# FLASH register map
Vendor: Texas Instruments
Peripheral module from a debugger description file (folder UCD3138R032RSM).
Registers are 32-bit, read-write, no defined reset value unless marked. A register's access mark holds for its fields unless they carry their own. Offsets are as the file gives them; lines under a group give offsets from that group; [hi:lo] are bit positions; {n}, {i} and the like mark numbered series; 'fields as' and 'values as' point back to an identical list; <NAME> marks a mode.

## FLASH (part 1 of 2) — This is the MMR space for the flash wrapper. The flash wrapper is targeting multiple microcontroller platforms. The flash wrapper is a module that manages complex flash read, program and erase memory operations. The system is also given direct access to read flash memory contents directly for each instantiated flash bank through FBAP ports.
0x00 DFTEN — DFT Enable Register Allows control of flash wrapper test features. When set, DFT* registers in this aperture open for write access. When cleared, DFT* registers are read-only. This register is blocked for writes after a 1 is written to the CMDEXEC register and prior to STATCMD.DONE being set by the flash wrapper hardware.
  [0] ENABLE — Enable Test Features
    0=DISABLED (Command); 1=ENABLED (Command)
0x00 CMDEXEC — Command Execute Register: Initiates execution of the command specified in the CMDTYPE register. This register is blocked for writes after being written to 1 and prior to STATCMD.DONE being set by the flash wrapper hardware. flash wrapper hardware clears this register after the processing of the command has completed.
  [0] VAL — Command Execute value Initiates execution of the command specified in the CMDTYPE register.
    0=NOEXECUTE (Command will not execute or is not executing in flash wrapper); 1=EXECUTE (Command will execute or is executing in flash wrapper)
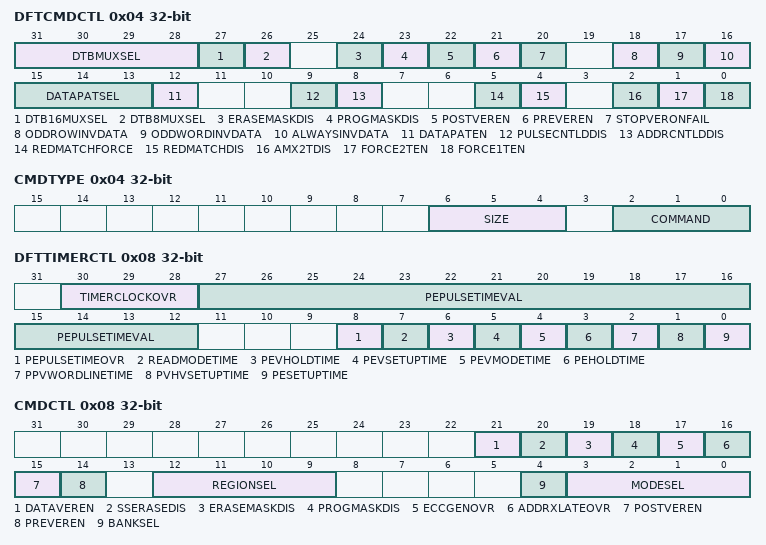
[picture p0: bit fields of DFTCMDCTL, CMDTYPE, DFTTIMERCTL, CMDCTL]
0x04 DFTCMDCTL — DFT Command Control Register This register configures specific capabilities for test. This register is only writable when DFTEN.ENABLE is set. This register is blocked for writes after a 1 is written to the CMDEXEC register and prior to STATCMD.DONE being set by the flash wrapper hardware.
  [31:28] DTBMUXSEL — DTB Mux Select This field will form the select for the primary DTB mux. This mux selects up to 16 sets of 32-bit fields of internal signals to be present to the 32-bit DTB output.
    15=MAXIMUM (Maximum value); 0=MINIMUM (Minimum value)
  [27] DTB16MUXSEL — DTB16 Mux Select This bit is valid when the flash wrapper DTB output bus width is less than 32 bits. Specifically, this bit is valid when the DTB width is 16 bits or less. When this is the case, then DTB16MUXSEL is used to select either the upper or lower 16-bit portion of the native 32-bit DTB bus. 8-bit portion of the 16-bit DTB value.
    1=UPPER16BITS (Select upper 16 bits of 32-bit DTB); 0=LOWER16BITS (Select lower 16 bits of 32-bit DTB)
  [26] DTB8MUXSEL — DTB8 Mux Select This bit is valid when the flash wrapper DTB output bus width is less than 32 bits. Specifically, this bit is valid when the DTB width is 8 bits. When this is the case, then DTB16MUXSEL is used to select either the upper or lower 16-bit portion of the native 32-bit DTB bus. DTB8MUXSEL is then used to select the upper or lower 8-bit portion of the 16-bit DTB value.
    1=UPPER8BITS (Select upper 8 bits of 16-bit DTB); 0=LOWER8BITS (Select lower 8 bits of 16-bit DTB)
  [24] ERASEMASKDIS — Disable use of erase mask for erase Bit masking will not be used during erase verify. If any sectors fail the verify either before (prever) or after (postver) the operation, then all specified flash sectors will receive subsequent erase pulse.
    0=ENABLE; 1=DISABLE
  [23] PROGMASKDIS — Disable use of program mask for programming. Bit masking will not be used during program verify. If any bits fail the verify either before (prever) or after (postver) the operation, then all specified flash entries will receive subsequent program pulse.
    0=ENABLE; 1=DISABLE
  [22] POSTVEREN — Enable verify after program or erase
    0=DISABLE; 1=ENABLE
  [21] PREVEREN — Enable verify before program or erase. For program, bits already programmed to the requested value will be masked. For erase, sectors already erased will be masked.
    0=DISABLE; 1=ENABLE
  [20] STOPVERONFAIL — Stop verify on fail. If this bit is set, verify will halt when the first verify fail is detected. If command is program or erase, another program or erase pulse will be executed. If command is ReadVerify, comand will terminate.
    0=DISABLE; 1=ENABLE
  [18] ODDROWINVDATA — Invert data at odd row addresses for program or verify. The LSB of the row address is bit [4] of the bank address. This bit only applies when pattern data is used; i.e. the DATAPATEN bit is set. It will have no effect if CMDDATA is used.
    0=TRUE (Use true data); 1=INVERT (Use inverted data)
  [17] ODDWORDINVDATA — Invert data at odd bank addresses for program or verify. This bit only applies when pattern data is used; i.e. the DATAPATEN bit is set. It will have no effect if CMDDATA is used.
    0=TRUE (Use true data); 1=INVERT (Use inverted data)
  [16] ALWAYSINVDATA — Invert data always for program or verify. This bit only applies when pattern data is used; i.e. the DATAPATEN bit is set. It will have no effect if CMDDATA is used.
    0=TRUE (Use true data); 1=INVERT (Use inverted data)
  [15:13] DATAPATSEL — Select data pattern. Valid when DATAPATEN bit is set to 1. Overrides CMDDATA registers for program or verify.
    0=ALL0 (Set to all 0); 1=ALL1 (Set to all 1); 2=LOGCHKBRD (Set to logical checkerboard (0x01010101...))
  [12] DATAPATEN — Enable data pattern. Data pattern select in DATAPATSEL field will override data from CMDDATA registers for use as program or verify data.
    0=DISABLE; 1=ENABLE
  [9] PULSECNTLDDIS — Override pulse counter enable. When set, the state machine pulse counter will not be loaded when a command is initiated.
    0=ENABLE; 1=DISABLE
  [8] ADDRCNTLDDIS — Override address counter enable. When set, the state machine address counter will not be loaded when a command is initiated.
    0=ENABLE; 1=DISABLE
  [5] REDMATCHFORCE — Force redundancy match. If set to 1, repair configuration encoded in the flash bank trim will be forced for every access.
    0=DISABLE; 1=ENABLE
  [4] REDMATCHDIS — Disable redundancy matching. Any repair configuration encoded into the bank trim bits is disabled.
    0=ENABLE; 1=DISABLE
  [2] AMX2TDIS — 2T address mux disable control. When set to 1 2T address shifting is disabled. This bit can only be enabled for reads. Indeterminate behavior will result if this bit is set during program/erase.
    0=ENABLE; 1=DISABLE
  [1] FORCE2TEN — Force 2T Enable - Force 2T access to regions that are designated as 1T. Regions designated as 2T will still be accessed as 2T.
    0=DISABLE; 1=ENABLE
  [0] FORCE1TEN — Force 1T Enable - Force 1T access to regions that are designated as 2T. Regions designated as 1T will still be accessed as 1T.
    0=DISABLE; 1=ENABLE
0x04 CMDTYPE — Command Type Register This register specifies the type of command to be executed by the flash wrapper hardware. This register is blocked for writes after CMDEXEC is written to a 1 and prior to STATCMD.DONE being set by the hardware to indicate that command execution has completed.
  [6:4] SIZE — Command size
    0=ONEWORD (Operate on 1 flash word); 1=TWOWORD (Operate on 2 flash words); 2=FOURWORD (Operate on 4 flash words); 3=EIGHTWORD (Operate on 8 flash words); 4=SECTOR (Operate on a flash sector); 5=BANK (Operate on an entire flash bank)
  [2:0] COMMAND — Command type
    0=NOOP (No Operation); 1=PROGRAM; 2=ERASE; 3=READVERIFY__SECRET_ENUM (ReadVerify - Perform a standalone ReadVerify operation.); 4=MODECHANGE (Mode Change - Perform a mode change only, no other operation.); 5=CLEARSTATUS (Clear Status - Clear status bits in FW_SMSTAT only.); 6=BLANKVERIFY (Blank Verify - Check whether a flash word is in the erased state. This command may only be used with CMDTYPE.SIZE = ONEWORD)
0x08 DFTTIMERCTL — DFT Timer Control Register This allows some configuration of timing values for various phases of flash operations for test. These time values are hard-coded for functional execution. This register is only writable when DFT.ENABLE is set. This register is blocked for writes after a 1 is written to the CMDEXEC register and prior to STATCMD.DONE being set by the flash wrapper hardware.
  [30:28] TIMERCLOCKOVR — Override Timer clock frequency using an ICG-based clock divide mechanism. To divide the timer clock, pulses can be skipped based on settings in this field. By default, this field is 0, which corresponds to no division on the timer clock.
    0=NODIVIDE (No divide on timer clock); {v}=DIVIDEBY{v+1} (Divide timer clock by {v+1}) (v=1..7)
  [27:12] PEPULSETIMEVAL — Program/Erase Pulse Time Value If operation is a program, this value gets loaded into bits [15:0] of the timer when the PEPULSETIMEVALOVR field is set to 1. If operation is an erase, this value gets loaded into bits [19:4] of the timer when the PEPULSETIMEVALOVR field is set to 1.
    0xFFFF=MAXIMUM (Maximum value); 1=MINIMUM (Minimum value)
  [8] PEPULSETIMEOVR — Override Program/Erase Pulse Time If set, this will force the program or erase pulse time to be overridden with the value in the PEPULSETIMEVAL field. If not set, then a hard-coded value will be used for this pulse time.
    0=FUNCTIONAL (Use hard-wired (Functional) timer value); 1=OVERRIDE (Use value from the PE_PULSE_TIME field for time value)
  [7] READMODETIME — Read Mode Change Time
    0=FUNCTIONAL (Use hard-wired (Functional) timer value); 1=TWOXFUNCTIONAL (Use 2x the hard-wired (functional) time value)
  [6] PEVHOLDTIME — Program/Erase Verify Hold Time
    values as READMODETIME
  [5] PEVSETUPTIME — Program/Erase Verify Setup Time
    values as READMODETIME
  [4] PEVMODETIME — Program/Erase Verify Mode Change Time
    values as READMODETIME
  [3] PEHOLDTIME — Program/Erase Hold Time
    values as READMODETIME
  [2] PPVWORDLINETIME — Program and Program Verify Wordline Switching Time
    values as READMODETIME
  [1] PVHVSETUPTIME — Program VHV Setup Time
    values as READMODETIME
  [0] PESETUPTIME — Program/Erase Setup Time
    values as READMODETIME
0x08 CMDCTL — Command Control Register This register configures specific capabilities of the state machine for related to the execution of a command. This register is blocked for writes after CMDEXEC is written to a 1 and prior to STATCMD.DONE being set by the hardware to indicate that command execution has completed.
  [21] DATAVEREN — Enable invalid data verify. This checks for 0->1 transitions in the memory when a program operation is initiated. If such a transition is found, the program will fail with an error without executing the program.
    0=DISABLE; 1=ENABLE
  [20] SSERASEDIS — Disable Stair-Step Erase. If set, the default VHV trim voltage setting will be used for all erase pulses. By default, this bit is reset, meaning that the VHV voltage will be stepped during successive erase pulses. The step count, step voltage, begin and end voltages are all hard-wired.
    0=ENABLE; 1=DISABLE
  [19] ERASEMASKDIS — Disable use of erase mask for erase Bit masking will not be used during erase verify. If one or more sectors fail the verify either before (prever) or after (postver) the operation, then all specified flash sectors will receive subsequent erase pulse.
    0=ENABLE; 1=DISABLE
  [18] PROGMASKDIS — Disable use of program mask for programming. Bit masking will not be used during program verify. If one or more bits fail the verify either before (prever) or after (postver) the operation, then all specified flash entries will receive subsequent program pulse.
    0=ENABLE; 1=DISABLE
  [17] ECCGENOVR — Override hardware generation of ECC data for program. Use data written to CMDDATAECC*.
    0=NOOVERRIDE (Do not override); 1=OVERRIDE
  [16] ADDRXLATEOVR — Override hardware address translation of address in CMDADDR from a system address to a bank address and bank ID. Use data written to CMDADDR directly as the bank address. Use the value written to CMDCTL.BANKSEL directly as the bank ID. Use the value written to CMDCTL.REGIONSEL directly as the region ID.
    0=NOOVERRIDE (Do not override); 1=OVERRIDE
  [15] POSTVEREN — Enable verify after program or erase
    0=DISABLE; 1=ENABLE
  [14] PREVEREN — Enable verify before program or erase. For program, bits already programmed to the requested value will be masked. For erase, sectors already erased will be masked.
    0=DISABLE; 1=ENABLE
  [12:9] REGIONSEL — Bank Region A specific region ID can be written to this field to indicate to which region an operation is to be applied if CMDCTL.ADDRXLATEOVR is set.
    1=MAIN (Main Region); 2=NONMAIN (Non-Main Region); 4=TRIM (Trim Region); 8=ENGR (Engr Region)
  [4] BANKSEL — Bank Select A specific Bank ID can be written to this field to indicate to which bank an operation is to be applied if CMDCTL.ADDRXLATEOVR is set.
  [3:0] MODESEL — Mode This field is only used for the Mode Change command type. Otherwise, bank and pump modes are set automaticlly through the NW hardware.
    0=READ (Read Mode); 2=RDMARG0 (Read Margin 0 Mode); 4=RDMARG1 (Read Margin 1 Mode); 6=RDMARG0B (Read Margin 0B Mode); 7=RDMARG1B (Read Margin 1B Mode); 9=PGMVER (Program Verify Mode); 10=PGMSW (Program Single Word); 11=ERASEVER (Erase Verify Mode); 12=ERASESECT (Erase Sector); 14=PGMMW (Program Multiple Word); 15=ERASEBNK (Erase Bank)
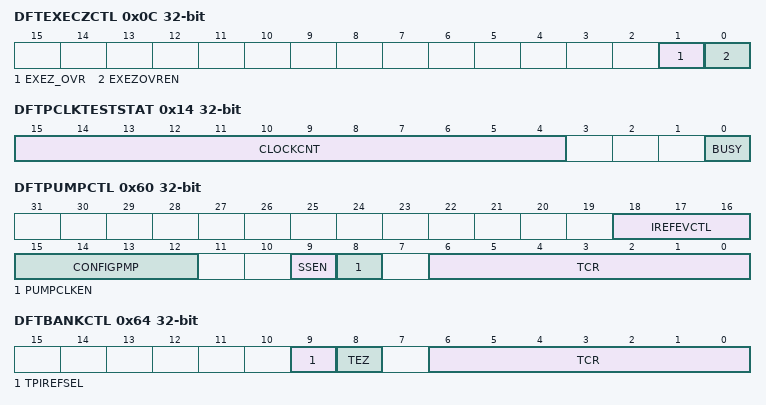
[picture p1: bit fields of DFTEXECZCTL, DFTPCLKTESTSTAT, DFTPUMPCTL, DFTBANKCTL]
0x0C DFTEXECZCTL — DFT EXECUTEZ control register. This register allows direct control of the EXECUTEZ to bank and pump for test. This register is only writable when DFTEN.ENABLE is set. This register is blocked for writes after a 1 is written to the CMDEXEC register and prior to STATCMD.DONE being set by the flash wrapper hardware.
  [1] EXEZ_OVR — Override value to be applied to EXECUTEZ
    0=ZERO (Set EXECUTEZ to 0); 1=ONE (Set EXECUTEZ to 1)
  [0] EXEZOVREN — Enable override of EXECUTEZ Note that when this bit is set, the flash wrapper has control of the bank pins.
    0=DISABLE; 1=ENABLE
0x10 DFTPCLKTESTCTL — DFT Pump Clock Test Control Register. This register controls hardware features that allow the pump clock to be characterized for trim development. This register is only writable when DFTEN.ENABLE is set. This register is blocked for writes after a 1 is written to the CMDEXEC register and prior to STATCMD.DONE being set by the flash wrapper hardware.
  [0] ENABLE — Enable the state machine which sequences measurement of pump clock frequency.
    0=DISABLE; 1=ENABLE
0x14 DFTPCLKTESTSTAT ro — DFT Pump Clock Test Status Register. This register shows status reported by the hardware features that allow the pump clock to be characterized for trim development. This register is only writable when DFTEN.ENABLE is set.
  [15:4] CLOCKCNT — Indicates the core clock count captured during the pump clock measurement.
    0=MINIMUM (Minimum count value); 0xFFF=MAXIMUM (Maximum count value)
  [0] BUSY — Indicates that a pump clock measurement is in progress.
    0=COMPLETE (Indicates test complete); 1=INPROGRESS (Indicates test in progress)
0x20 IIDX ro — Interrupt Index Register: The IIDX register provides the highest priority enabled interrupt index. PSD compliant register. Note that it is not recommended to use this register if the system clock is running at a slower clock frequency than the flash wrapper clock. If this is the case, then reading this register may fail to update the RIS register correctly. The MIS register can be read directly, and a write to ICLR can be used to clear interrupts when this clock relationship is present.
  [0] STAT — Indicates which interrupt has fired. 0x0 means no event pending. The priority order is fixed. On each read, only one interrupt is indicated. On a read, the current interrupt (highest priority) is automatically cleared by the hardware and the corresponding interrupt flags in the RIS and MIS are cleared as well. After a read from the CPU (not from the debug interface), the register must be updated with the next highest priority interrupt.
    1=DONE (DONE Interrupt Pending); 0=NO_INTR (No Interrupt Pending)
0x20 CMDADDR — Command Address Register: This register forms the target address of a command. The use cases are as follows: 1) For single-word program, this address indicates the flash bank word to be programmed. 2) For multi-word program, this address indicates the first flash bank address for the program. The address will be incremented for further words. 3) For sector erase, this address indicates the sector to be erased. 4) For bank erase, the address indicates the bank to be erased. Note the address written to this register will be submitted for translation to the flash wrapper address translation interface, and the translated address will be used to access the bank. However, if the CMDCTL.ADDRXLATEOVR bit is set, then the address written to this register will be used directly as the bank address. This register is blocked for writes after a 1 is written to the CMDEXEC register and prior to STATCMD.DONE being set by the flash wrapper hardware.
  [31:0] VAL — Address value
    0xFFFFFFFF=MAXIMUM (Maximum value of [VAL]); 0=MINIMUM (Minimum value of [VAL])
0x24 CMDBYTEN — Command Program Byte Enable Register: This register forms a per-byte enable for programming data. For data bytes to be programmed, a 1 must be written to the corresponding bit in this register. Normally, all bits are written to 1, allowing program of full flash words. However, leaving some bits 0 allows programming of 8-bit, 16-bit, 32-bit or 64-bit portions of a flash word. During verify, data bytes read from the flash will not be checked if the corresponding CMDBYTEN bit is 0. ECC data bytes are protected by the 1-2 MSB bits in this register, depending on the presence of ECC and the flash word data width. This register is blocked for writes after a 1 is written to the CMDEXEC register and prior to STATCMD.DONE being set by the flash wrapper hardware. This register is written to all 0 after the completion of all flash wrapper commands.
  [7:0] VAL — Command Byte Enable value. A 1-bit per flash word byte value is placed in this register.
0x28 IMASK — Interrupt Mask Register: The IMASK register holds the current interrupt mask settings. Masked interrupts are read in the MIS register. PSD compliant register.
  [0] DONE — Interrupt mask for DONE: 0: Interrupt is disabled in MIS register 1: Interrupt is enabled in MIS register
    0=DISABLED (Interrupt is masked out); 1=ENABLED (Interrupt will request an interrupt service routine and corresponding bit in [IPSTANDARD.MIS] will be set)
0x2C CMDDATAINDEX — Command Program Data Index Register: When multiple data registers are available for multi-word program, this register can be written with an index which points to one of the data registers. When a write to CMDDATA* is done, the data will be written to the physical data register indexed by the value in this register. Up to 8 data registers can be present, so this register can be written with 0x0 to 0x7. If less than 8 data registers are present, successive MSB bits of this register are ignored when indexing the CMDDATA* registers. This register is blocked for writes after a 1 is written to the CMDEXEC register and prior to STATCMD.DONE being set by the flash wrapper hardware.
  [2:0] VAL — Data register index
    7=MAXIMUM (Maximum value of [VAL]); 0=MINIMUM (Minimum value of [VAL])
0x30 RIS ro — Raw Interrupt Status Register: The RIS register reflects all pending interrupts, regardless of masking. The RIS register allows the user to implement a poll scheme. A flag set in this register can be cleared by writing a 1 to the ICLR register bit even if the corresponding IMASK bit is not enabled. A flag can be set by software by writing a 1 to the ISET register. Reading the IIDX register will also clear the corresponding bit in RIS. PSD compliant register.
  [0] DONE — Flash wrapper operation completed. This interrupt bit is set by firmware or the corresponding bit in the ISET register. It is cleared by the corresponding bit in in the ICLR register or reading the IIDX register when this interrupt is the highest priority.
    0=CLR (Interrupt did not occur); 1=SET (Interrupt occurred)
0x30 CMDDATA0 — Command Data Register 0 This register forms the data for a command. For DATAWIDTH == 128: This register represents bits 31:0 of flash word data register 0. For DATAWIDTH == 64: This register represents bits 31:0 of flash word data register 0. This register is blocked for writes after a 1 is written to the CMDEXEC register and prior to STATCMD.DONE being set by the flash wrapper hardware. This register is used to aggregate masking for bits that do not require additional program pulses during program operations, and will be written to all 1 after the completion of all flash wrapper commands. Use cases for the CMDDATA* registers are as follows: 1) Program - These registers contain the data to be programmed. 2) Erase - These registers are not used.
  [31:0] VAL — A 32-bit data value is placed in this field.
    values as CMDADDR.VAL
0x34 CMDDATA1 — Command Data Register 1 This register forms the data for a command. For DATAWIDTH == 128: This register represents bits 63:32 of flash word data register 0. For DATAWIDTH == 64: This register represents bits 63:32 of flash word data register 0. This register is blocked for writes after a 1 is written to the CMDEXEC register and prior to CMDSTAT.DONE being set by the flash wrapper hardware. This register is used to aggregate masking for bits that do not require additional program pulses during program operations, and will be written to all 1 after the completion of all flash wrapper commands. Use cases for the CMDDATA* registers are as follows: 1) Program - These registers contain the data to be programmed. 2) Erase - These registers are not used.
  fields as CMDDATA0
0x38 MIS ro — Masked Interrupt Status Register: The MIS register is a bit-wise AND of the contents of the IMASK and RIS registers. This is kept mainly for ARM compatibility, and has limited use since the highest priority interrupt index is returned through the IIDX register. PSD compliant register.
  [0] DONE — Flash wrapper operation completed. This masked interrupt bit reflects the bitwise AND of the corresponding RIS and IMASK bits.
    0=CLR (Masked interrupt did not occur); 1=SET (Masked interrupt occurred)
0x38 CMDDATA2 — Command Data Register 2 This register forms the data for a command. For DATAWIDTH == 128: This register represents bits 95:64 of flash word data register 0. For DATAWIDTH == 64: This register represents bits 31:0 of flash word data register 1. This register is blocked for writes after a 1 is written to the CMDEXEC register and prior to STATCMD.DONE being set by the flash wrapper hardware. This register is used to aggregate masking for bits that do not require additional program pulses during program operations, and will be written to all 1 after the completion of all flash wrapper commands. Use cases for the CMDDATA* registers are as follows: 1) Program - These registers contain the data to be programmed. 2) Erase - These registers are not used.
  fields as CMDDATA0
0x3C CMDDATA3 — Command Data Register 3 This register forms the data for a command. For DATAWIDTH == 128: This register represents bits 127:96 of flash word data register 0. For DATAWIDTH == 64: This register represents bits 63:32 of flash word data register 1. This register is blocked for writes after a 1 is written to the CMDEXEC register and prior to STATCMD.DONE being set by the flash wrapper hardware. This register is used to aggregate masking for bits that do not require additional program pulses during program operations, and will be written to all 1 after the completion of all flash wrapper commands. Use cases for the CMDDATA* registers are as follows: 1) Program - These registers contain the data to be programmed. 2) Erase - These registers are not used.
  fields as CMDDATA0
0x40 ISET wo — Interrupt Set Register: The ISET register allows software to write a 1 to set corresponding interrupt. Safety: This meets a safety requirement to allow software diagnostics to trigger interrupts. PSD compliant register.
  [0] DONE — 0: No effect 1: Set the DONE interrupt in the RIS register
    0=NO_EFFECT (Writing a 0 has no effect); 1=SET (Set [IPSTANDARD.RIS] bit)
{0x40+4i} DFTDATARED{i} (i=0..7) — DFT Redundancy Data Register {i} This register is used when testing the redundant columns in the flash. It acts as an extension of the CMDDATA* registers. The bits in this register correspond to flash data word register {i}. In addition, this register is used to aggregate masking for bits that do not require additional program pulses during program operations. The original data written to this register will be lost during program command execution. Use cases for this register are as follows: 1) Program - Contains the data to be programmed. 2) Erase - Not used. This register is only writable when DFTEN.ENABLE is set. This register is blocked for writes after a 1 is written to the CMDEXEC register and prior to STATCMD.DONE being set by the flash wrapper hardware.
  [3:0] VAL — Data for redundant bits
0x40 CMDDATA4 — Command Data Register 4 This register forms the data for a command. For DATAWIDTH == 128: This register represents bits 31:0 of flash word data register 1. For DATAWIDTH == 64: This register represents bits 31:0 of flash word data register 2. This register is blocked for writes after a 1 is written to the CMDEXEC register and prior to STATCMD.DONE being set by the flash wrapper hardware. This register is used to aggregate masking for bits that do not require additional program pulses during program operations, and will be written to all 1 after the completion of all flash wrapper commands. Use cases for the CMDDATA* registers are as follows: 1) Program - These registers contain the data to be programmed. 2) Erase - These registers are not used.
  [31:0] VAL — A 32-bit data value is placed in this field. T
    values as CMDADDR.VAL
0x44 CMDDATA5 — Command Data Register 5 This register forms the data for a command. For DATAWIDTH == 128: This register represents bits 63:32 of flash word data register 1. For DATAWIDTH == 64: This register represents bits 63:32 of flash word data register 2. This register is blocked for writes after a 1 is written to the CMDEXEC register and prior to STATCMD.DONE being set by the flash wrapper hardware. This register is used to aggregate masking for bits that do not require additional program pulses during program operations, and will be written to all 1 after the completion of all flash wrapper commands. Use cases for the CMDDATA* registers are as follows: 1) Program - These registers contain the data to be programmed. 2) Erase - These registers are not used.
  fields as CMDDATA0
0x48 ICLR wo — Interrupt Clear Register. The ICLR register allows allows software to write a 1 to clear corresponding interrupt. PSD compliant register.
  [0] DONE — 0: No effect 1: Clear the DONE interrupt in the RIS register
    0=NO_EFFECT (Writing a 0 has no effect); 1=CLR (Clear [IPSTANDARD.RIS] bit)
0x48 CMDDATA6 — Command Data Register 6 This register forms the data for a command. For DATAWIDTH == 128: This register represents bits 95:64 of flash word data register 1. For DATAWIDTH == 64: This register represents bits 31:0 of flash word data register 3. This register is blocked for writes after a 1 is written to the CMDEXEC register and prior to STATCMD.DONE being set by the flash wrapper hardware. This register is used to aggregate masking for bits that do not require additional program pulses during program operations, and will be written to all 1 after the completion of all flash wrapper commands. Use cases for the CMDDATA* registers are as follows: 1) Program - These registers contain the data to be programmed. 2) Erase - These registers are not used.
  fields as CMDDATA0
0x4C CMDDATA7 — Command Data Register 7 This register forms the data for a command. For DATAWIDTH == 128: This register represents bits 127:96 of flash word data register 1. For DATAWIDTH == 64: This register represents bits 63:32 of flash word data register 3. This register is blocked for writes after a 1 is written to the CMDEXEC register and prior to STATCMD.DONE being set by the flash wrapper hardware. This register is used to aggregate masking for bits that do not require additional program pulses during program operations, and will be written to all 1 after the completion of all flash wrapper commands. Use cases for the CMDDATA* registers are as follows: 1) Program - These registers contain the data to be programmed. 2) Erase - These registers are not used.
  fields as CMDDATA0
0x50 CMDDATA8 — Command Data Register 8 This register forms the data for a command. For DATAWIDTH == 128: This register represents bits 31:0 of flash word data register 2. For DATAWIDTH == 64: This register represents bits 31:0 of flash word data register 4. This register is blocked for writes after a 1 is written to the CMDEXEC register and prior to STATCMD.DONE being set by the flash wrapper hardware. This register is used to aggregate masking for bits that do not require additional program pulses during program operations, and will be written to all 1 after the completion of all flash wrapper commands. Use cases for the CMDDATA* registers are as follows: 1) Program - These registers contain the data to be programmed. 2) Erase - These registers are not used.
  fields as CMDDATA0
0x54 CMDDATA9 — Command Data Register 9 This register forms the data for a command. For DATAWIDTH == 128: This register represents bits 63:32 of flash word data register 2. For DATAWIDTH == 64: This register represents bits 63:32 of flash word data register 4. This register is blocked for writes after a 1 is written to the CMDEXEC register and prior to STATCMD.DONE being set by the flash wrapper hardware. This register is used to aggregate masking for bits that do not require additional program pulses during program operations, and will be written to all 1 after the completion of all flash wrapper commands. Use cases for the CMDDATA* registers are as follows: 1) Program - These registers contain the data to be programmed. 2) Erase - These registers are not used.
  fields as CMDDATA0
0x58 CMDDATA10 — Command Data Register 10 This register forms the data for a command. For DATAWIDTH == 128: This register represents bits 95:64 of flash word data register 2. For DATAWIDTH == 64: This register represents bits 31:0 of flash word data register 5. This register is blocked for writes after a 1 is written to the CMDEXEC register and prior to STATCMD.DONE being set by the flash wrapper hardware. This register is used to aggregate masking for bits that do not require additional program pulses during program operations, and will be written to all 1 after the completion of all flash wrapper commands. Use cases for the CMDDATA* registers are as follows: 1) Program - These registers contain the data to be programmed. 2) Erase - These registers are not used.
  fields as CMDDATA0
0x5C CMDDATA11 — Command Data Register 11 This register forms the data for a command. For DATAWIDTH == 128: This register represents bits 127:96 of flash word data register 2. For DATAWIDTH == 64: This register represents bits 63:32 of flash word data register 5. This register is blocked for writes after a 1 is written to the CMDEXEC register and prior to STATCMD.DONE being set by the flash wrapper hardware. This register is used to aggregate masking for bits that do not require additional program pulses during program operations, and will be written to all 1 after the completion of all flash wrapper commands. Use cases for the CMDDATA* registers are as follows: 1) Program - These registers contain the data to be programmed. 2) Erase - These registers are not used.
  fields as CMDDATA0
0x60 DFTPUMPCTL — DFT Pump Control Register This allows some configuration of pump parameters during test. This register is only writable when DFTEN.ENABLE is set. This register is blocked for writes after a 1 is written to the CMDEXEC register and prior to STATCMD.DONE being set by the flash wrapper hardware.
  [18:16] IREFEVCTL — IREFEV control IREFVRD, REFTC, IREFCONST, IREFCCOR blocks in IREFEV
  [15:12] CONFIGPMP — Pump configuration control. LP, HP operation
  [9] SSEN — Dither control for oscillator Enumeration: 0: Disable Dither 1: Enable Dither
    0=DISABLE; 1=ENABLE
  [8] PUMPCLKEN — Allows direct control of the pump oscillator which is used to generate pumpclk. Normally, enable/disable of pumpclk is under flash wrapper state machine control. This bit allows system to enable the clock independently.
    0=HWCTL (Allow pump clock oscillator to be controlled by hardware.); 1=ENABLE (Force pump clock oscillator to be enabled.)
  [6:0] TCR — TCR test mode to be applied to the pump
    127=MAXIMUM (Maximum value); 0=MINIMUM (Minimum value)
0x60 CMDDATA12 — Command Data Register 12 This register forms the data for a command. For DATAWIDTH == 128: This register represents bits 31:0 of flash word data register 3. For DATAWIDTH == 64: This register represents bits 31:0 of flash word data register 6. This register is blocked for writes after a 1 is written to the CMDEXEC register and prior to STATCMD.DONE being set by the flash wrapper hardware. This register is used to aggregate masking for bits that do not require additional program pulses during program operations, and will be written to all 1 after the completion of all flash wrapper commands. Use cases for the CMDDATA* registers are as follows: 1) Program - These registers contain the data to be programmed. 2) Erase - These registers are not used.
  fields as CMDDATA0
0x64 DFTBANKCTL — DFT Bank Control Register This allows some configuration of bank parameters during test. This register is only writable when DFTEN.ENABLE is set. This register is blocked for writes after a 1 is written to the CMDEXEC register and prior to STATCMD.DONE being set by the flash wrapper hardware.
  [9] TPIREFSEL — For MP bank designs, selects whether IREF or IREFTIM is reflected to the flash test pads during TCR mode 25.
    0=IREFSELECT (IREF is selected); 1=IREFTIMSELECT (IREFTIM is selected)
  [8] TEZ — When set, TEZ is asserted to the flash banks. Which banks get the asserted signal is determined by the BANKSELECT field in CMDCTL. 0x0 Do no assert TEZ 0x1 Assert TEZ
    0=ASSERT (Assert TEZ); 1=NEGATE (Do not assert TEZ)
  [6:0] TCR — TCR test mode to be applied to the bank
    127=MAXIMUM (Maximum value); 0=MINIMUM (Minimum value)
0x64 CMDDATA13 — Command Data Register 13 This register forms the data for a command. For DATAWIDTH == 128: This register represents bits 63:32 of flash word data register 3. For DATAWIDTH == 64: This register represents bits 63:32 of flash word data register 6. This register is blocked for writes after a 1 is written to the CMDEXEC register and prior to STATCMD.DONE being set by the flash wrapper hardware. This register is used to aggregate masking for bits that do not require additional program pulses during program operations, and will be written to all 1 after the completion of all flash wrapper commands. Use cases for the CMDDATA* registers are as follows: 1) Program - These registers contain the data to be programmed. 2) Erase - These registers are not used.
  fields as CMDDATA0
0x68 CMDDATA14 — Command Data Register 14 This register forms the data for a command. For DATAWIDTH == 128: This register represents bits 95:64 of flash word data register 3. For DATAWIDTH == 64: This register represents bits 31:0 of flash word data register 7. This register is blocked for writes after a 1 is written to the CMDEXEC register and prior to STATCMD.DONE being set by the flash wrapper hardware. This register is used to aggregate masking for bits that do not require additional program pulses during program operations, and will be written to all 1 after the completion of all flash wrapper commands. Use cases for the CMDDATA* registers are as follows: 1) Program - These registers contain the data to be programmed. 2) Erase - These registers are not used.
  fields as CMDDATA0
0x6C CMDDATA15 — Command Data Register 15 This register forms the data for a command. For DATAWIDTH == 128: This register represents bits 127:96 of flash word data register 3. For DATAWIDTH == 64: This register represents bits 63:32 of flash word data register 7. This register is blocked for writes after a 1 is written to the CMDEXEC register and prior to STATCMD.DONE being set by the flash wrapper hardware. This register is used to aggregate masking for bits that do not require additional program pulses during program operations, and will be written to all 1 after the completion of all flash wrapper commands. Use cases for the CMDDATA* registers are as follows: 1) Program - These registers contain the data to be programmed. 2) Erase - These registers are not used.
  fields as CMDDATA0
{0x30+4i} CMDDATA{i} (i=16..19) — Command Data Register {i} This register forms the data for a command. For DATAWIDTH == 128: This register represents bits {32i-481}:{32i-512} of flash word data register 4. This register is blocked for writes after a 1 is written to the CMDEXEC register and prior to STATCMD.DONE being set by the flash wrapper hardware. This register is used to aggregate masking for bits that do not require additional program pulses during program operations, and will be written to all 1 after the completion of all flash wrapper commands. Use cases for the CMDDATA* registers are as follows: 1) Program - These registers contain the data to be programmed. 2) Erase - These registers are not used.
  fields as CMDDATA0
